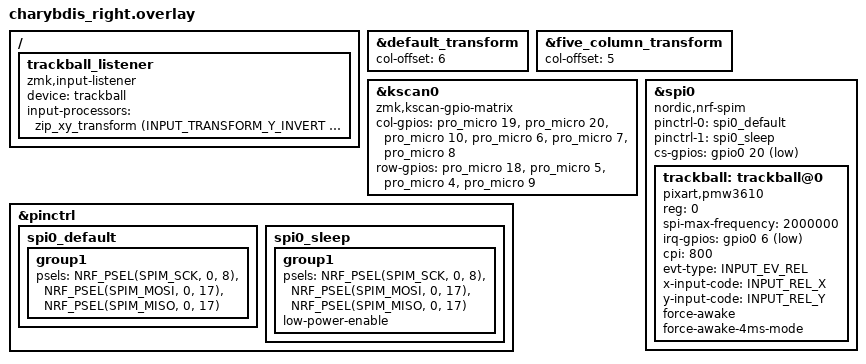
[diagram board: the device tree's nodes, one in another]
#include "charybdis.dtsi"
#include <dt-bindings/zmk/input_transform.h>
#include <dt-bindings/zmk/matrix_transform.h>
#include <zephyr/dt-bindings/input/input-event-codes.h>

#define INPUT_EV_KEY 0x01               /**< Key event */
#define INPUT_EV_REL 0x02               /**< Relative coordinate event */
#define INPUT_EV_ABS 0x03               /**< Absolute coordinate event */
#define INPUT_EV_MSC 0x04               /**< Miscellaneous event */
#define INPUT_EV_VENDOR_START 0xf0      /**< Vendor specific event start */
#define INPUT_EV_VENDOR_STOP 0xff       /**< Vendor specific event stop */

#define INPUT_REL_X 0x00                /**< Relative X coordinate */
#define INPUT_REL_Y 0x01                /**< Relative Y coordinate */
#define INPUT_REL_WHEEL 0x08            /**< Relative wheel coordinate */
#define INPUT_REL_HWHEEL 0x06           /**< Relative horizontal wheel coordinate */
#define INPUT_REL_MISC 0x09             /**< Relative misc coordinate */

&default_transform {
	col-offset = <6>;
};

&five_column_transform {
	col-offset = <5>;
};

&kscan0 {
	compatible = "zmk,kscan-gpio-matrix";
	
	col-gpios
		= <&pro_micro 19 (GPIO_ACTIVE_HIGH | GPIO_PULL_DOWN)>
		, <&pro_micro 20 (GPIO_ACTIVE_HIGH | GPIO_PULL_DOWN)>
		, <&pro_micro 10 (GPIO_ACTIVE_HIGH | GPIO_PULL_DOWN)>
		, <&pro_micro 6 (GPIO_ACTIVE_HIGH | GPIO_PULL_DOWN)>
		, <&pro_micro 7 (GPIO_ACTIVE_HIGH | GPIO_PULL_DOWN)>
		, <&pro_micro 8 (GPIO_ACTIVE_HIGH | GPIO_PULL_DOWN)>
		;

	row-gpios
		= <&pro_micro 18 GPIO_ACTIVE_HIGH>
		, <&pro_micro 5 GPIO_ACTIVE_HIGH>
		, <&pro_micro 4 GPIO_ACTIVE_HIGH>
		, <&pro_micro 9 GPIO_ACTIVE_HIGH>
		;
};

&pinctrl {
    spi0_default: spi0_default {
        group1 {
            psels = <NRF_PSEL(SPIM_SCK, 0, 8)>,
                <NRF_PSEL(SPIM_MOSI, 0, 17)>,
                <NRF_PSEL(SPIM_MISO, 0, 17)>;
        };
    };

    spi0_sleep: spi0_sleep {
        group1 {
            psels = <NRF_PSEL(SPIM_SCK, 0, 8)>,
                <NRF_PSEL(SPIM_MOSI, 0, 17)>,
                <NRF_PSEL(SPIM_MISO, 0, 17)>;
            low-power-enable;
        };
    };
};

&spi0 {
    status = "okay";
    compatible = "nordic,nrf-spim";
    pinctrl-0 = <&spi0_default>;
    pinctrl-1 = <&spi0_sleep>;
    pinctrl-names = "default", "sleep";
    cs-gpios = <&gpio0 20 GPIO_ACTIVE_LOW>;

    trackball: trackball@0 {
        status = "okay";
        compatible = "pixart,pmw3610";
        reg = <0>;
        spi-max-frequency = <2000000>;
        irq-gpios = <&gpio0 6 (GPIO_ACTIVE_LOW | GPIO_PULL_UP)>;
        cpi = <800>;
        evt-type = <INPUT_EV_REL>;
        x-input-code = <INPUT_REL_X>;
        y-input-code = <INPUT_REL_Y>;

        force-awake;
        /* keep the sensor awake while ZMK activity state is ACTIVE,
           fallback to normal downshift mode after ZMK goes into IDLE / SLEEP mode.
           thus, the sensor would be a `wakeup-source` */

        force-awake-4ms-mode;
        /* while force-awake is acitvated, enable this mode to force sampling per 
           4ms, where the default sampling rate is 8ms. */
        /* NOTE: apply this mode if you need 250Hz with direct USB connection. */
    };

};

/ {
  trackball_listener: trackball_listener {
    compatible = "zmk,input-listener";
    device = <&trackball>;
    input-processors = <&zip_xy_transform (INPUT_TRANSFORM_Y_INVERT | INPUT_TRANSFORM_X_INVERT | INPUT_TRANSFORM_XY_SWAP )>;
  };
}; 


